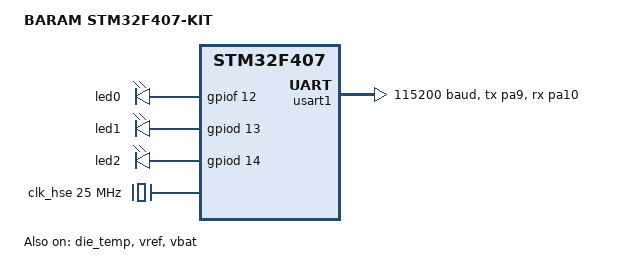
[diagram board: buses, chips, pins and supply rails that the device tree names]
/*
 * Copyright (c) 2017 Linaro Limited
 *
 * SPDX-License-Identifier: Apache-2.0
 */

/dts-v1/;
#include <st/f4/stm32f407Xg.dtsi>
#include <st/f4/stm32f407v(e-g)tx-pinctrl.dtsi>
#include <zephyr/dt-bindings/input/input-event-codes.h>

/ {
	model = "BARAM STM32F407-KIT";
	compatible = "st,stm32f407_kit";

	chosen {
		// zephyr,shell-uart = &usart2;
		zephyr,sram = &sram0;
		zephyr,flash = &flash0;
		zephyr,ccm = &ccm0;
		zephyr,console = &usart1;
	};

	leds {
		compatible = "gpio-leds";

		led0: led_0 {
			gpios = <&gpiof 12 GPIO_ACTIVE_HIGH>;
		};

		led1: led_1 {
			gpios = <&gpiod 13 GPIO_ACTIVE_HIGH>;
		};
    
		led2: led_2 {
			gpios = <&gpiod 14 GPIO_ACTIVE_HIGH>;
		};    
	};

};

&clk_lsi {
	status = "okay";
};

&clk_hse {
	clock-frequency = <DT_FREQ_M(25)>;
	status = "okay";
};

&pll {
	div-m = <25>;
	mul-n = <336>;
	div-p = <2>;
	div-q = <7>;
	clocks = <&clk_hse>;
	status = "okay";
};

&rcc {
	clocks = <&pll>;
	clock-frequency = <DT_FREQ_M(168)>;
	ahb-prescaler = <1>;
	apb1-prescaler = <4>;
	apb2-prescaler = <2>;
};

&die_temp {
	status = "okay";
};

&vref {
	status = "okay";
};

&vbat {
	status = "okay";
};

&dma1 {
	status = "okay";
};

&usart1 {
	pinctrl-0 = <&usart1_tx_pa9 &usart1_rx_pa10>;
	pinctrl-names = "default";
	current-speed = <115200>;
	status = "okay";
};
